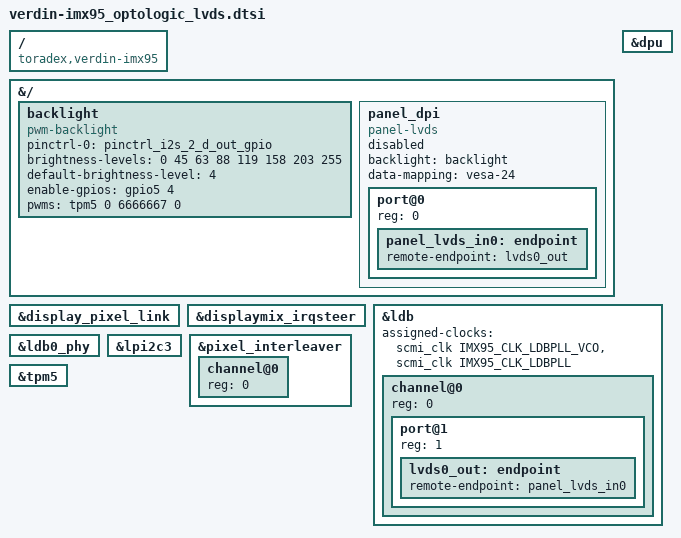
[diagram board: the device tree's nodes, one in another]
// SPDX-License-Identifier: GPL-2.0-or-later OR MIT
/*
 * Common LVDS/backlight/enablement for Verdin iMX95 Optologic panels
 */

#include <dt-bindings/clock/fsl,imx95-clock.h>
#include <dt-bindings/gpio/gpio.h>

/ {
	compatible = "toradex,verdin-imx95";
};

&{/} {
	backlight: backlight {
		compatible = "pwm-backlight";
		pinctrl-names = "default";
		pinctrl-0 = <&pinctrl_i2s_2_d_out_gpio>;
		brightness-levels = <0 45 63 88 119 158 203 255>;
		default-brightness-level = <4>;
		/* Verdin I2S_2_D_OUT (SODIMM 46) */
		enable-gpios = <&gpio5 4 GPIO_ACTIVE_HIGH>;
		/* Verdin PWM_2 (SODIMM 16) */
		pwms = <&tpm5 0 6666667 0>;
	};

	panel_dpi: panel_dpi { /* name to keep the compatibility with colibri panel */
		compatible = "panel-lvds";
		#address-cells = <1>;
		#size-cells = <0>;
		backlight = <&backlight>;
		data-mapping = "vesa-24";
		status = "disable";

		port@0 {
			reg = <0>;

			panel_lvds_in0: endpoint {
				remote-endpoint = <&lvds0_out>;
			};
		};
	};
};

&display_pixel_link {
	status = "okay";
};

&displaymix_irqsteer {
	status = "okay";
};

&dpu {
	status = "okay";
};

&ldb {
	#address-cells = <1>;
	#size-cells = <0>;
	assigned-clocks = <&scmi_clk IMX95_CLK_LDBPLL_VCO>,
			  <&scmi_clk IMX95_CLK_LDBPLL>;
	status = "okay";

	channel@0 {
		reg = <0>;
		#address-cells = <1>;
		#size-cells = <0>;
		status = "okay";

		port@1 {
			reg = <1>;

			lvds0_out: endpoint {
				remote-endpoint = <&panel_lvds_in0>;
			};
		};
	};
};

&ldb0_phy {
	status = "okay";
};

/* Verdin I2C_2_DSI */
&lpi2c3 {
	#address-cells = <1>;
	#size-cells = <0>;
	status = "okay";
};

&pixel_interleaver {
	#address-cells = <1>;
	#size-cells = <0>;
	status = "okay";

	channel@0 {
		reg = <0>;
		status = "okay";
	};
};

/* Verdin PWM_2 */
&tpm5 {
	status = "okay";
};
